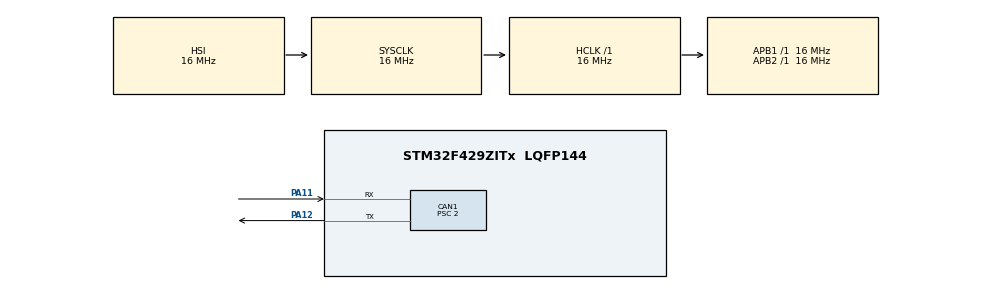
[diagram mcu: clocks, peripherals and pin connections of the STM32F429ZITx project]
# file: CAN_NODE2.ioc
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CAN1.BS1=CAN_BS1_4TQ
CAN1.BS2=CAN_BS2_3TQ
CAN1.CalculateBaudRate=1000000
CAN1.CalculateTimeBit=1000
CAN1.CalculateTimeQuantum=125.0
CAN1.Prescaler=2
Mcu.Family=STM32F4
Mcu.Name=STM32F429ZITx
Mcu.Package=LQFP144
NVIC.CAN1_RX0_IRQn=true\:0\:0\:false\:false\:true\:true\:true\:true
NVIC.PriorityGroup=NVIC_PRIORITYGROUP_4
PA11.Mode=CAN_Activate
PA11.Signal=CAN1_RX
PA12.Mode=CAN_Activate
PA12.Signal=CAN1_TX
PA13.Mode=Serial_Wire
PA13.Signal=SYS_JTMS-SWDIO
PA14.Mode=Serial_Wire
PA14.Signal=SYS_JTCK-SWCLK
ProjectManager.HeapSize=0x200
ProjectManager.StackSize=0x400
ProjectManager.TargetToolchain=STM32CubeIDE
RCC.AHBFreq_Value=16000000
RCC.APB1Freq_Value=16000000
RCC.APB2Freq_Value=16000000
RCC.CortexFreq_Value=16000000
RCC.HSE_VALUE=25000000
RCC.HSI_VALUE=16000000
RCC.LSE_VALUE=32768
RCC.SYSCLKFreq_VALUE=16000000
RCC.VCOOutputFreq_Value=192000000
board=custom

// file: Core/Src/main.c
/* USER CODE BEGIN Header */
/**
  ******************************************************************************
  * @file           : main.c
  * @brief          : Main program body
  ******************************************************************************
  * @attention
  *
  * Copyright (c) 2024 STMicroelectronics.
  * All rights reserved.
  *
  * This software is licensed under terms that can be found in the LICENSE file
  * in the root directory of this software component.
  * If no LICENSE file comes with this software, it is provided AS-IS.
  *
  ******************************************************************************
  */
/* USER CODE END Header */
#include "main.h"

CAN_HandleTypeDef hcan1;

/* USER CODE BEGIN PV */

CAN_TxHeaderTypeDef TxHeader;
CAN_RxHeaderTypeDef RxHeader;

uint8_t TxData[8];
uint8_t RxData[8];

uint32_t TxMailbox;

/* USER CODE END PV */

void SystemClock_Config(void);
static void MX_GPIO_Init(void);
static void MX_CAN1_Init(void);

int main(void)
{

  /* MCU Configuration--------------------------------------------------------*/

  /* Reset of all peripherals, Initializes the Flash interface and the Systick. */
  HAL_Init();

  /* Configure the system clock */
  SystemClock_Config();

  /* Initialize all configured peripherals */
  MX_GPIO_Init();
  MX_CAN1_Init();
  /* USER CODE BEGIN 2 */

  HAL_CAN_Start(&hcan1);

  // Activate the notification
  HAL_CAN_ActivateNotification(&hcan1, CAN_IT_RX_FIFO0_MSG_PENDING);

  TxHeader.DLC = 2;  // data length
  TxHeader.IDE = CAN_ID_STD;
  TxHeader.RTR = CAN_RTR_DATA;
  TxHeader.StdId = 0x103;  // ID

  TxData[0] = 200;  // ms delay
  TxData[1] = 20;  // loop rep

  /* USER CODE END 2 */

  /* Infinite loop */
  /* USER CODE BEGIN WHILE */
  while (1)
  {

	  //HAL_CAN_AddTxMessage(&hcan1, &TxHeader, TxData, &TxMailbox);

	  HAL_Delay(1000);
    /* USER CODE END WHILE */

  }
}

void SystemClock_Config(void)
{
  RCC_OscInitTypeDef RCC_OscInitStruct = {0};
  RCC_ClkInitTypeDef RCC_ClkInitStruct = {0};

  /** Configure the main internal regulator output voltage
  */
  __HAL_RCC_PWR_CLK_ENABLE();
  __HAL_PWR_VOLTAGESCALING_CONFIG(PWR_REGULATOR_VOLTAGE_SCALE3);

  /** Initializes the RCC Oscillators according to the specified parameters
  * in the RCC_OscInitTypeDef structure.
  */
  RCC_OscInitStruct.OscillatorType = RCC_OSCILLATORTYPE_HSI;
  RCC_OscInitStruct.HSIState = RCC_HSI_ON;
  RCC_OscInitStruct.HSICalibrationValue = RCC_HSICALIBRATION_DEFAULT;
  RCC_OscInitStruct.PLL.PLLState = RCC_PLL_NONE;
  if (HAL_RCC_OscConfig(&RCC_OscInitStruct) != HAL_OK)
  {
    Error_Handler();
  }

  /** Initializes the CPU, AHB and APB buses clocks
  */
  RCC_ClkInitStruct.ClockType = RCC_CLOCKTYPE_HCLK|RCC_CLOCKTYPE_SYSCLK
                              |RCC_CLOCKTYPE_PCLK1|RCC_CLOCKTYPE_PCLK2;
  RCC_ClkInitStruct.SYSCLKSource = RCC_SYSCLKSOURCE_HSI;
  RCC_ClkInitStruct.AHBCLKDivider = RCC_SYSCLK_DIV1;
  RCC_ClkInitStruct.APB1CLKDivider = RCC_HCLK_DIV1;
  RCC_ClkInitStruct.APB2CLKDivider = RCC_HCLK_DIV1;

  if (HAL_RCC_ClockConfig(&RCC_ClkInitStruct, FLASH_LATENCY_0) != HAL_OK)
  {
    Error_Handler();
  }
}

static void MX_CAN1_Init(void)
{

  hcan1.Instance = CAN1;
  hcan1.Init.Prescaler = 2;
  hcan1.Init.Mode = CAN_MODE_NORMAL;
  hcan1.Init.SyncJumpWidth = CAN_SJW_1TQ;
  hcan1.Init.TimeSeg1 = CAN_BS1_4TQ;
  hcan1.Init.TimeSeg2 = CAN_BS2_3TQ;
  hcan1.Init.TimeTriggeredMode = DISABLE;
  hcan1.Init.AutoBusOff = DISABLE;
  hcan1.Init.AutoWakeUp = DISABLE;
  hcan1.Init.AutoRetransmission = DISABLE;
  hcan1.Init.ReceiveFifoLocked = DISABLE;
  hcan1.Init.TransmitFifoPriority = DISABLE;
  if (HAL_CAN_Init(&hcan1) != HAL_OK)
  {
    Error_Handler();
  }
  /* USER CODE BEGIN CAN1_Init 2 */

  CAN_FilterTypeDef canfilterconfig;

  canfilterconfig.FilterActivation = CAN_FILTER_ENABLE;
  canfilterconfig.FilterBank = 10;  // which filter bank to use from the assigned ones
  canfilterconfig.FilterFIFOAssignment = CAN_FILTER_FIFO0;
  canfilterconfig.FilterIdHigh = 0x446;
  canfilterconfig.FilterIdLow = 0;
  canfilterconfig.FilterMaskIdHigh = 0;
  canfilterconfig.FilterMaskIdLow = 0;
  canfilterconfig.FilterMode = CAN_FILTERMODE_IDMASK;
  canfilterconfig.FilterScale = CAN_FILTERSCALE_32BIT;
  canfilterconfig.SlaveStartFilterBank = 0;  // doesn't matter in single can controllers

  HAL_CAN_ConfigFilter(&hcan1, &canfilterconfig);

  /* USER CODE END CAN1_Init 2 */

}

static void MX_GPIO_Init(void)
{

  /* GPIO Ports Clock Enable */
  __HAL_RCC_GPIOA_CLK_ENABLE();

}

/* USER CODE BEGIN 4 */

void HAL_CAN_RxFifo0MsgPendingCallback(CAN_HandleTypeDef *hcan1)
{
	HAL_CAN_GetRxMessage(hcan1, CAN_RX_FIFO0, &RxHeader, RxData);
	//HAL_GPIO_TogglePin(GPIOA, GPIO_PIN_3);

}

/* USER CODE END 4 */

void Error_Handler(void)
{
  __disable_irq();
  while (1)
  {
  }
}
